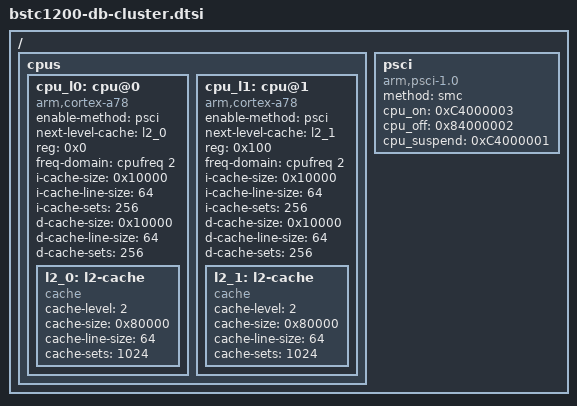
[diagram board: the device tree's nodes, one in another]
// SPDX-License-Identifier: GPL-2.0+

/ { 
	cpus {
		#address-cells = <1>;
		#size-cells = <0>;

		cpu_l0: cpu@0 {
			compatible = "arm,cortex-a78", "arm,armv8";
			device_type = "cpu";
			enable-method = "psci";
			next-level-cache = <&l2_0>;
			reg = <0x0>;
			freq-domain = <&cpufreq 2>;

			i-cache-size = <0x10000>;
			i-cache-line-size = <64>;
			i-cache-sets = <256>;
			d-cache-size = <0x10000>;
			d-cache-line-size = <64>;
			d-cache-sets = <256>;

			l2_0: l2-cache {
				compatible = "cache";
				cache-level = <2>;
				cache-size = <0x80000>;
				cache-line-size = <64>;
				cache-sets = <1024>;
			};
		};

		cpu_l1: cpu@1 {
			compatible = "arm,cortex-a78", "arm,armv8";
			device_type = "cpu";
			enable-method = "psci";
			next-level-cache = <&l2_1>;
			reg = <0x100>;
			freq-domain = <&cpufreq 2>;

			i-cache-size = <0x10000>;
			i-cache-line-size = <64>;
			i-cache-sets = <256>;
			d-cache-size = <0x10000>;
			d-cache-line-size = <64>;
			d-cache-sets = <256>;

			l2_1: l2-cache {
				compatible = "cache";
				cache-level = <2>;
				cache-size = <0x80000>;
				cache-line-size = <64>;
				cache-sets = <1024>;
			};
		};
	};

	psci {
		compatible	= "arm,psci-1.0";
		method		= "smc";
		cpu_on		= <0xC4000003>;
		cpu_off		= <0x84000002>;
		cpu_suspend	= <0xC4000001>;
	};
};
